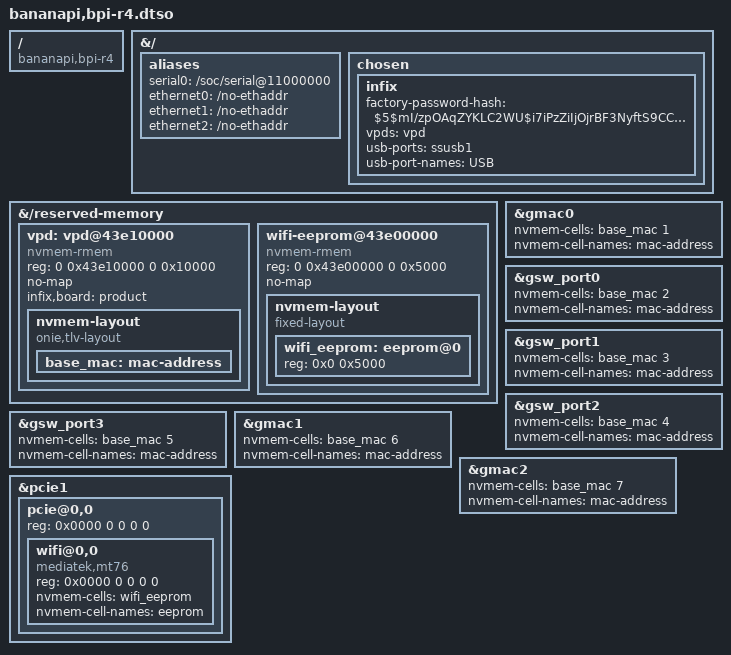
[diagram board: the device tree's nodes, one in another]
// SPDX-License-Identifier: (GPL-2.0 OR MIT)
/dts-v1/;
/plugin/;

/ {
	compatible = "bananapi,bpi-r4", "mediatek,mt7988a";
};

/*
 * The upstream mt7988a-bananapi-bpi-r4.dtsi sets stdout-path = "serial0:..."
 * but the aliases node there only has ethernet entries.  Linux resolves
 * stdout-path by looking in /aliases, so we must add serial0 here.
 * Path references in overlay aliases cannot use &label, so use the full path.
 */
&{/} {
	aliases {
		serial0 = "/soc/serial@11000000";
		/*
		 * U-Boot writes its random ethaddr into the nodes behind the
		 * ethernet aliases, which would take precedence over the VPD
		 * addresses below.  An overlay cannot delete properties in
		 * U-Boot, so point the aliases at nothing instead.
		 */
		ethernet0 = "/no-ethaddr";
		ethernet1 = "/no-ethaddr";
		ethernet2 = "/no-ethaddr";
	};

	chosen {
		infix {
			/* Default admin user password: 'admin' */
			factory-password-hash = "$5$mI/zpOAqZYKLC2WU$i7iPzZiIjOjrBF3NyftS9CCq8dfYwHwrmUK097Jca9A";
			vpds = <&vpd>;
			usb-ports = <&ssusb1>;
			usb-port-names = "USB";
		};
	};
};

/*
 * Product VPD, an ONIE TLV that the boot loader copies from the aux
 * partition into reserved memory.  The region is zeroed when there is
 * no VPD, which leaves the layout without cells.  Ports reference the
 * base MAC address with an index, <&base_mac N>, and get base + N as
 * their permanent address.
 */
&{/reserved-memory} {
	vpd: vpd@43e10000 {
		compatible = "nvmem-rmem";
		reg = <0 0x43e10000 0 0x10000>;
		no-map;
		infix,board = "product";

		nvmem-layout {
			compatible = "onie,tlv-layout";

			base_mac: mac-address {
				#nvmem-cell-cells = <1>;
			};
		};
	};
};

/* Port addresses: VPD base MAC + 1 .. + 7 */
&gmac0 {
	nvmem-cells = <&base_mac 1>;
	nvmem-cell-names = "mac-address";
};

&gsw_port0 {
	nvmem-cells = <&base_mac 2>;
	nvmem-cell-names = "mac-address";
};

&gsw_port1 {
	nvmem-cells = <&base_mac 3>;
	nvmem-cell-names = "mac-address";
};

&gsw_port2 {
	nvmem-cells = <&base_mac 4>;
	nvmem-cell-names = "mac-address";
};

&gsw_port3 {
	nvmem-cells = <&base_mac 5>;
	nvmem-cell-names = "mac-address";
};

&gmac1 {
	nvmem-cells = <&base_mac 6>;
	nvmem-cell-names = "mac-address";
};

&gmac2 {
	nvmem-cells = <&base_mac 7>;
	nvmem-cell-names = "mac-address";
};

/*
 * EEPROM for a WiFi card in mPCIe CN14, for cards shipped without one.
 * The boot loader copies /mnt/aux/wifi-eeprom.bin here, or zeroes the
 * region, which the driver rejects for the card's own EEPROM.
 */
&{/reserved-memory} {
	wifi-eeprom@43e00000 {
		compatible = "nvmem-rmem";
		reg = <0 0x43e00000 0 0x5000>;
		no-map;

		nvmem-layout {
			compatible = "fixed-layout";
			#address-cells = <1>;
			#size-cells = <1>;

			wifi_eeprom: eeprom@0 {
				reg = <0x0 0x5000>;
			};
		};
	};
};

&pcie1 {
	pcie@0,0 {
		reg = <0x0000 0 0 0 0>;
		#address-cells = <3>;
		#size-cells = <2>;
		device_type = "pci";
		ranges;

		wifi@0,0 {
			compatible = "mediatek,mt76";
			reg = <0x0000 0 0 0 0>;
			nvmem-cells = <&wifi_eeprom>;
			nvmem-cell-names = "eeprom";
		};
	};
};
